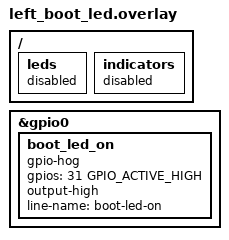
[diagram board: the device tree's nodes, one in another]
/ {
    leds {
        status = "disabled";
    };

    indicators {
        status = "disabled";
    };
};

&gpio0 {
    boot_led_on {
        gpio-hog;
        gpios = <31 GPIO_ACTIVE_HIGH>;
        output-high;
        line-name = "boot-led-on";
    };
};
